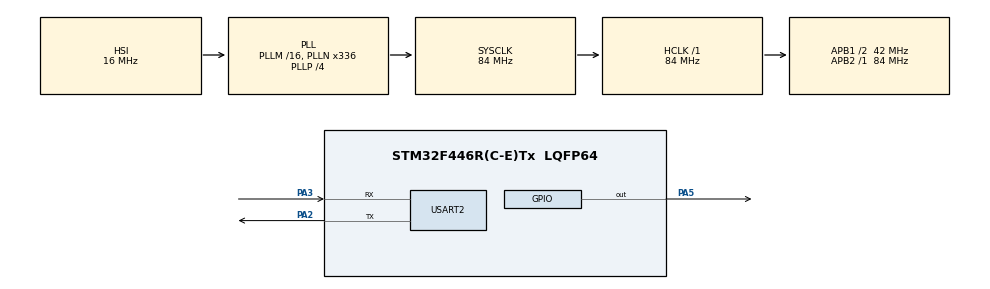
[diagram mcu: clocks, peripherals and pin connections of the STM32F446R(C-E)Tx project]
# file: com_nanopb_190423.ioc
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Mcu.Family=STM32F4
Mcu.Name=STM32F446R(C-E)Tx
Mcu.Package=LQFP64
NVIC.FPU_IRQn=true\:0\:0\:false\:false\:true\:true
NVIC.PriorityGroup=NVIC_PRIORITYGROUP_0
NVIC.USART2_IRQn=true\:0\:0\:false\:false\:true\:true
PA2.Mode=Asynchronous
PA2.Signal=USART2_TX
PA3.Mode=Asynchronous
PA3.Signal=USART2_RX
PA5.Signal=GPIO_Output
PH0-OSC_IN.Mode=HSE-External-Oscillator
PH0-OSC_IN.Signal=RCC_OSC_IN
PH1-OSC_OUT.Mode=HSE-External-Oscillator
PH1-OSC_OUT.Signal=RCC_OSC_OUT
ProjectManager.HeapSize=0x200
ProjectManager.StackSize=0x400
ProjectManager.TargetToolchain=MDK-ARM V5
RCC.AHBFreq_Value=84000000
RCC.APB1CLKDivider=RCC_HCLK_DIV2
RCC.APB1Freq_Value=42000000
RCC.APB1TimFreq_Value=84000000
RCC.APB2Freq_Value=84000000
RCC.APB2TimFreq_Value=84000000
RCC.CortexFreq_Value=84000000
RCC.FLatency-AdvancedSettings=FLASH_LATENCY_2
RCC.HCLKFreq_Value=84000000
RCC.HSE_VALUE=8000000
RCC.HSI_VALUE=16000000
RCC.LSE_VALUE=32768
RCC.PLLN=336
RCC.PLLP=RCC_PLLP_DIV4
RCC.SYSCLKFreq_VALUE=84000000
RCC.SYSCLKSource=RCC_SYSCLKSOURCE_PLLCLK
RCC.USBFreq_Value=168000000
RCC.VCOOutputFreq_Value=336000000
USART2.VirtualMode=VM_ASYNC
board=NUCLEO-F446RE

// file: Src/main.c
/**
  ******************************************************************************
  * File Name          : main.c
  * Description        : Main program body
  ******************************************************************************
  ** This notice applies to any and all portions of this file
  * that are not between comment pairs USER CODE BEGIN and
  * USER CODE END. Other portions of this file, whether
  * inserted by the user or by software development tools
  * are owned by their respective copyright owners.
  *
  * COPYRIGHT(c) 2019 STMicroelectronics
  *
  * Redistribution and use in source and binary forms, with or without modification,
  * are permitted provided that the following conditions are met:
  *   1. Redistributions of source code must retain the above copyright notice,
  *      this list of conditions and the following disclaimer.
  *   2. Redistributions in binary form must reproduce the above copyright notice,
  *      this list of conditions and the following disclaimer in the documentation
  *      and/or other materials provided with the distribution.
  *   3. Neither the name of STMicroelectronics nor the names of its contributors
  *      may be used to endorse or promote products derived from this software
  *      without specific prior written permission.
  *
  * THIS SOFTWARE IS PROVIDED BY THE COPYRIGHT HOLDERS AND CONTRIBUTORS "AS IS"
  * AND ANY EXPRESS OR IMPLIED WARRANTIES, INCLUDING, BUT NOT LIMITED TO, THE
  * IMPLIED WARRANTIES OF MERCHANTABILITY AND FITNESS FOR A PARTICULAR PURPOSE ARE
  * DISCLAIMED. IN NO EVENT SHALL THE COPYRIGHT HOLDER OR CONTRIBUTORS BE LIABLE
  * FOR ANY DIRECT, INDIRECT, INCIDENTAL, SPECIAL, EXEMPLARY, OR CONSEQUENTIAL
  * DAMAGES (INCLUDING, BUT NOT LIMITED TO, PROCUREMENT OF SUBSTITUTE GOODS OR
  * SERVICES; LOSS OF USE, DATA, OR PROFITS; OR BUSINESS INTERRUPTION) HOWEVER
  * CAUSED AND ON ANY THEORY OF LIABILITY, WHETHER IN CONTRACT, STRICT LIABILITY,
  * OR TORT (INCLUDING NEGLIGENCE OR OTHERWISE) ARISING IN ANY WAY OUT OF THE USE
  * OF THIS SOFTWARE, EVEN IF ADVISED OF THE POSSIBILITY OF SUCH DAMAGE.
  *
  ******************************************************************************
  */

#include "main.h"
#include "stm32f4xx_hal.h"
#include "usart.h"
#include "gpio.h"

/* USER CODE BEGIN Includes */
#include "pb_encode.h"
#include "pb_decode.h"
#include "command.pb.h"
/* USER CODE END Includes */

/* USER CODE BEGIN PV */
/* Private variables ---------------------------------------------------------*/

/* USER CODE END PV */

void SystemClock_Config(void);

/* USER CODE BEGIN PFP */
/* Private function prototypes -----------------------------------------------*/

/* USER CODE END PFP */

/* USER CODE BEGIN 0 */
//Variables for UART communication with protobuf.
uint8_t buffer[128]; //in TransmitProto
size_t message_length;
bool status;

//Variables, store the command numbers
int32_t cmd_1 = 95;
int32_t cmd_2 = 96;

//Variables for UART communication.
uint8_t rx_index = 0;
uint8_t rx_data;
uint8_t rx_buffer[20];
//uint8_t python_buffer[]="hello\n";//torolheto

//Send messages with protobuf.
void TransmitProto(int32_t command_id)
{
	CommandMessage omessage = CommandMessage_init_zero;
	pb_ostream_t stream = pb_ostream_from_buffer(buffer, sizeof(buffer));//this stream will write to our buffer
	omessage.id = command_id;
	status = pb_encode(&stream, CommandMessage_fields, &omessage);//encode message
	message_length = stream.bytes_written;
	//Check for errors:
	if(!status)
	{
		HAL_GPIO_WritePin(GPIOA, GPIO_PIN_5, GPIO_PIN_SET);
	}
}
//Receive protobuf messages from serial.
void ReceiveProto()
{
	CommandMessage imessage = CommandMessage_init_zero;
	pb_istream_t istream = pb_istream_from_buffer(rx_buffer, message_length);//stream that reads from rx_buffer
	status = pb_decode(&istream, CommandMessage_fields, &imessage);//decode
	if(!status)
	{
		HAL_GPIO_WritePin(GPIOA, GPIO_PIN_5, GPIO_PIN_SET);
	}
	if(imessage.id == cmd_1)
	{
		HAL_GPIO_WritePin(GPIOA, GPIO_PIN_5, GPIO_PIN_SET);
	}else if(imessage.id == cmd_2)
	{
		HAL_GPIO_WritePin(GPIOA, GPIO_PIN_5, GPIO_PIN_RESET);
	}
}

//Receive 'classic' messages with UART.
void HAL_UART_RxCpltCallback(UART_HandleTypeDef *huart)
{
	if (huart->Instance == USART2)
	{
		//clear the buffer
		if (rx_index == 0)
		{
			for(int i = 0; i < 20; i++)
			{
				rx_buffer[i] = 0;
			}
		}
		//if the character received is other than 'enter' (ascii 13) -> save data to buffer
		//else, transmit the data buffer, and set rx_index to 0.
		if (rx_data != 13)
		{
			rx_buffer[rx_index++] = rx_data;
		}
		else
		{
			HAL_UART_Transmit(&huart2, rx_buffer, sizeof(rx_buffer), 100); //transmit data if the data is 13
			message_length = rx_index;
			ReceiveProto();
			rx_index = 0;
		}

		HAL_UART_Receive_IT(&huart2, &rx_data, 1);//receive data (one character only)
	}
}

/* USER CODE END 0 */

int main(void)
{

  /* MCU Configuration----------------------------------------------------------*/

  /* Reset of all peripherals, Initializes the Flash interface and the Systick. */
  HAL_Init();

  /* Configure the system clock */
  SystemClock_Config();

  /* Initialize all configured peripherals */
  MX_GPIO_Init();
  MX_USART2_UART_Init();

  /* USER CODE BEGIN 2 */
	HAL_UART_Receive_IT(&huart2, &rx_data, 1);
	//TransmitProto(150);
  /* USER CODE END 2 */

  /* Infinite loop */
  while (1)
  {
//		HAL_UART_Transmit(&huart2, python_buffer, sizeof(python_buffer), 10);
//		HAL_Delay(1000);
  /* USER CODE BEGIN 3 */
		//HAL_GPIO_TogglePin(GPIOA,GPIO_PIN_5);
		//HAL_Delay(500);
		//HAL_GPIO_WritePin(GPIOA, GPIO_PIN_5, GPIO_PIN_SET);
		//HAL_GPIO_WritePin(GPIOA, GPIO_PIN_5, GPIO_PIN_RESET);
  }
  /* USER CODE END 3 */

}

/** System Clock Configuration
*/
void SystemClock_Config(void)
{

  RCC_OscInitTypeDef RCC_OscInitStruct;
  RCC_ClkInitTypeDef RCC_ClkInitStruct;

    /**Configure the main internal regulator output voltage
    */
  __HAL_RCC_PWR_CLK_ENABLE();

  __HAL_PWR_VOLTAGESCALING_CONFIG(PWR_REGULATOR_VOLTAGE_SCALE3);

    /**Initializes the CPU, AHB and APB busses clocks
    */
  RCC_OscInitStruct.OscillatorType = RCC_OSCILLATORTYPE_HSI;
  RCC_OscInitStruct.HSIState = RCC_HSI_ON;
  RCC_OscInitStruct.HSICalibrationValue = 16;
  RCC_OscInitStruct.PLL.PLLState = RCC_PLL_ON;
  RCC_OscInitStruct.PLL.PLLSource = RCC_PLLSOURCE_HSI;
  RCC_OscInitStruct.PLL.PLLM = 16;
  RCC_OscInitStruct.PLL.PLLN = 336;
  RCC_OscInitStruct.PLL.PLLP = RCC_PLLP_DIV4;
  RCC_OscInitStruct.PLL.PLLQ = 2;
  RCC_OscInitStruct.PLL.PLLR = 2;
  if (HAL_RCC_OscConfig(&RCC_OscInitStruct) != HAL_OK)
  {
    _Error_Handler(__FILE__, __LINE__);
  }

    /**Initializes the CPU, AHB and APB busses clocks
    */
  RCC_ClkInitStruct.ClockType = RCC_CLOCKTYPE_HCLK|RCC_CLOCKTYPE_SYSCLK
                              |RCC_CLOCKTYPE_PCLK1|RCC_CLOCKTYPE_PCLK2;
  RCC_ClkInitStruct.SYSCLKSource = RCC_SYSCLKSOURCE_PLLCLK;
  RCC_ClkInitStruct.AHBCLKDivider = RCC_SYSCLK_DIV1;
  RCC_ClkInitStruct.APB1CLKDivider = RCC_HCLK_DIV2;
  RCC_ClkInitStruct.APB2CLKDivider = RCC_HCLK_DIV1;

  if (HAL_RCC_ClockConfig(&RCC_ClkInitStruct, FLASH_LATENCY_2) != HAL_OK)
  {
    _Error_Handler(__FILE__, __LINE__);
  }

    /**Configure the Systick interrupt time
    */
  HAL_SYSTICK_Config(HAL_RCC_GetHCLKFreq()/1000);

    /**Configure the Systick
    */
  HAL_SYSTICK_CLKSourceConfig(SYSTICK_CLKSOURCE_HCLK);

  /* SysTick_IRQn interrupt configuration */
  HAL_NVIC_SetPriority(SysTick_IRQn, 0, 0);
}

void _Error_Handler(char * file, int line)
{
  while(1)
  {
  }
}

/************************ (C) COPYRIGHT STMicroelectronics *****END OF FILE****/
